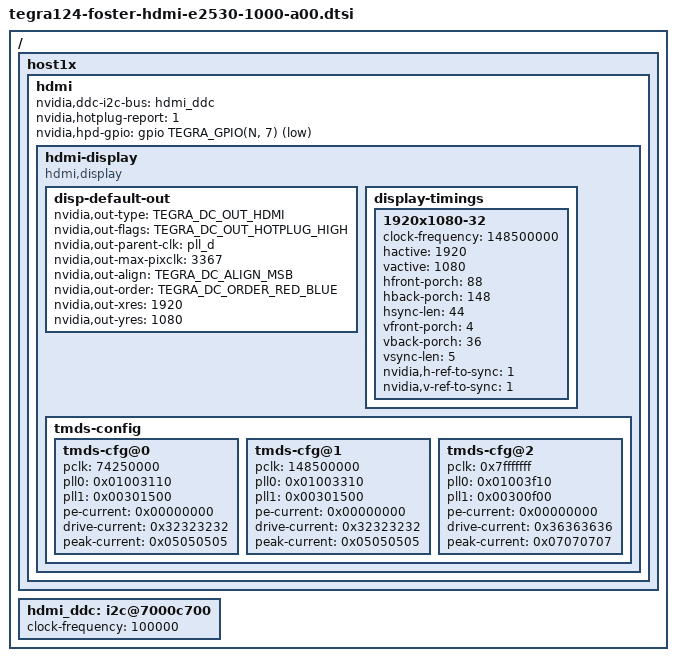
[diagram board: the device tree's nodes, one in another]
/*
 * arch/arm/boot/dts/tegra124-platforms/tegra124-foster-hdmi-e2530-1000-a00.dtsi
 *
 * Copyright (c) 2014, NVIDIA CORPORATION.  All rights reserved.
 *
 * This program is free software; you can redistribute it and/or modify
 * it under the terms of the GNU General Public License as published by
 * the Free Software Foundation; either version 2 of the License, or
 * (at your option) any later version.
 *
 * This program is distributed in the hope that it will be useful, but WITHOUT
 * ANY WARRANTY; without even the implied warranty of MERCHANTABILITY or
 * FITNESS FOR A PARTICULAR PURPOSE.  See the GNU General Public License for
 * more details.
 *
 * You should have received a copy of the GNU General Public License along
 * with this program; if not, write to the Free Software Foundation, Inc.,
 * 51 Franklin Street, Fifth Floor, Boston, MA  02110-1301, USA.
 */

#include <dt-bindings/display/tegra-dc.h>

/ {
	host1x {
		hdmi {
			status = "okay";
			nvidia,ddc-i2c-bus = <&hdmi_ddc>;
			nvidia,hotplug-report = <1>;
			nvidia,hpd-gpio = <&gpio TEGRA_GPIO(N, 7) 1>; /* PN7 */
			hdmi-display {
				status = "okay";
				compatible = "hdmi,display";
				disp-default-out {
					nvidia,out-type = <TEGRA_DC_OUT_HDMI>;
					nvidia,out-flags = <TEGRA_DC_OUT_HOTPLUG_HIGH>;
					nvidia,out-parent-clk = "pll_d";
					nvidia,out-max-pixclk = <3367>; /* KHZ2PICOS(297000) */
					nvidia,out-align = <TEGRA_DC_ALIGN_MSB>;
					nvidia,out-order = <TEGRA_DC_ORDER_RED_BLUE>;
					nvidia,out-xres = <1920>;
					nvidia,out-yres = <1080>;
				};
				display-timings {
					1920x1080-32 {
						clock-frequency = <148500000>;
						hactive = <1920>;
						vactive = <1080>;
						hfront-porch = <88>;
						hback-porch = <148>;
						hsync-len = <44>;
						vfront-porch = <4>;
						vback-porch = <36>;
						vsync-len = <5>;
						nvidia,h-ref-to-sync = <1>;
						nvidia,v-ref-to-sync = <1>;
					};
				};
				tmds-config {
					tmds-cfg@0 {
						pclk = <74250000>;
						pll0 = <0x01003110>;
						pll1 = <0x00301500>;
						pe-current = <0x00000000>;
						drive-current = <0x32323232>;
						peak-current = <0x05050505>;
					};
					tmds-cfg@1 {
						pclk = <148500000>;
						pll0 = <0x01003310>;
						pll1 = <0x00301500>;
						pe-current = <0x00000000>;
						drive-current = <0x32323232>;
						peak-current = <0x05050505>;
					};
					tmds-cfg@2 {
						pclk = <0x7fffffff>;
						pll0 = <0x01003f10>;
						pll1 = <0x00300f00>;
						pe-current = <0x00000000>;
						drive-current = <0x36363636>;
						peak-current = <0x07070707>;
					};
				};
			};
		};
	};
	hdmi_ddc: i2c@7000c700 {
		clock-frequency = <100000>;
	};
};

